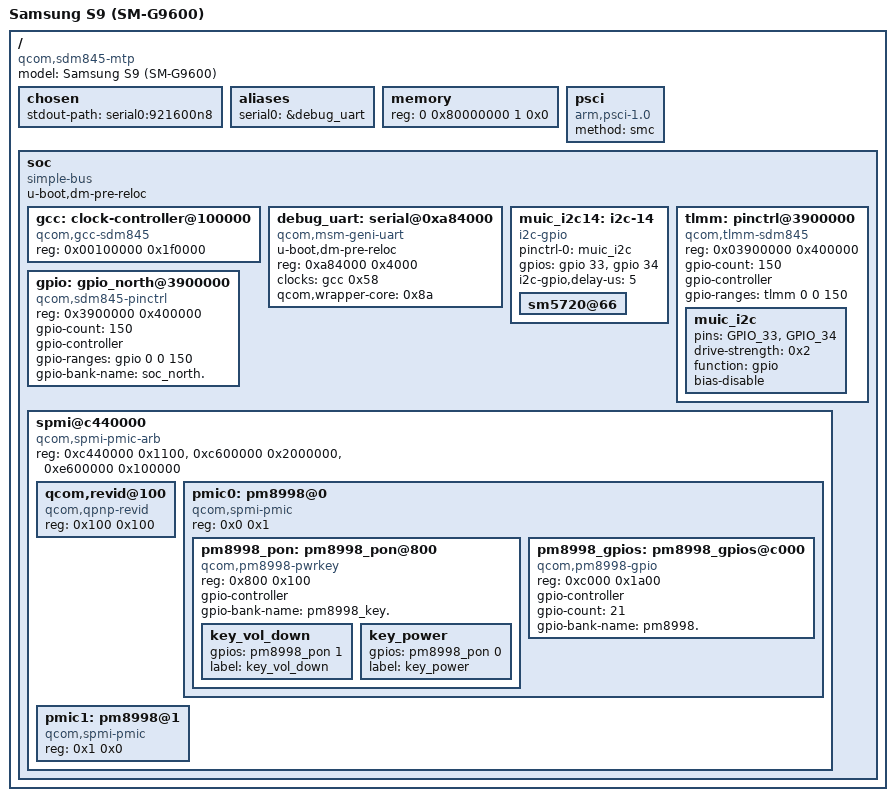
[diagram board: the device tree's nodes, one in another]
/*
 * Qualcomm APQ8096 based Dragonboard 820C board device tree source
 *
 * (C) Copyright 2017 Jorge Ramirez-Ortiz <jorge.ramirez-ortiz@linaro.org>
 *
 * SPDX-License-Identifier:	GPL-2.0+
 */

/dts-v1/;

#include "skeleton64.dtsi"

/ {
	model = "Samsung S9 (SM-G9600)";
	compatible = "qcom,sdm845-mtp", "qcom,sdm845", "qcom,mtp";
	#address-cells = <2>;
	#size-cells = <2>;

	chosen {
		stdout-path = "serial0:921600n8";
	};

	aliases {
		serial0 = &debug_uart;
	};

	memory {
		device_type = "memory";
		reg = <0 0x80000000 1 0x0>;
	};

	psci {
		compatible = "arm,psci-1.0";
		method = "smc";
	};

	soc: soc {
	    u-boot,dm-pre-reloc;
		#address-cells = <1>;
		#size-cells = <1>;
		ranges = <0 0 0 0xffffffff>;
		compatible = "simple-bus";

        gcc: clock-controller@100000 {
			compatible = "qcom,gcc-sdm845";
			reg = <0x00100000 0x1f0000>;
			#clock-cells = <1>;
			#reset-cells = <1>;
			#power-domain-cells = <1>;
		};

        debug_uart: serial@0xa84000 {
            u-boot,dm-pre-reloc;
		    compatible = "qcom,msm-geni-uart";
    		reg = <0xa84000 0x4000>;
    		reg-names = "se_phys";
    		clock-names = "se-clk";
    		clocks = <&gcc 0x58>;
    		//pinctrl-names = "default", "sleep";
    		//pinctrl-0 = <0x88>;
    		//pinctrl-1 = <0x89>;
    		qcom,wrapper-core = <0x8a>;
    		status = "ok";
    	};

        muic_i2c14: i2c-14 {
        	#address-cells = <1>;
        	#size-cells = <0>;
        	compatible = "i2c-gpio";
        	pinctrl-names = "muic";
        	pinctrl-0 = <&muic_i2c>;
        	gpios = <
               	&gpio 33 0 /* sda */
        	    &gpio 34 0 /* scl */
            >;
        	i2c-gpio,delay-us = <5>;

        	sm5720@66 {
        	};
        };

        gpio: gpio_north@3900000 {
			#gpio-cells = <2>;
			compatible = "qcom,sdm845-pinctrl";
			reg = <0x3900000 0x400000>;
			gpio-count = <150>;
			gpio-controller;
			gpio-ranges = <&gpio 0 0 150>;
			gpio-bank-name = "soc_north.";

			/*
			power button:
			volup 0x32
			voldown
			bixby


			.dir_conn_reg = (base == NORTH) ? base + 0xa4000 : \
            			((base == SOUTH) ? base + 0xa8000 : base + 0x9e000), \
			*/
		};

        tlmm: pinctrl@3900000 {
			compatible = "qcom,tlmm-sdm845";
			reg = <0x03900000 0x400000>;
			gpio-count = <150>;
			gpio-controller;
			#gpio-cells = <2>;
			gpio-ranges = <&tlmm 0 0 150>;

            muic_i2c: muic_i2c {
                        pins = "GPIO_33", "GPIO_34";
						drive-strength = <0x2>;
						function = "gpio";
						bias-disable;
			};

			/* DEBUG UART */
            /*
            qup_uart9_default: qup-uart9-default {
				pinmux {
					pins = "gpio4", "gpio5";
					function = "qup9";
				};
			};
			*/
		};

        spmi@c440000 {
			compatible = "qcom,spmi-pmic-arb";
			reg = <0xc440000 0x1100>,
			      <0xc600000 0x2000000>,
			      <0xe600000 0x100000>;
			//reg-names = "core", "chnls", "obsrvr", "intr", "cnfg";
			#address-cells = <0x1>;
			#size-cells = <0x1>;

            qcom,revid@100 {
					compatible = "qcom,qpnp-revid";
					reg = <0x100 0x100>;
					linux,phandle = <0x3ac>;
					phandle = <0x3ac>;
				};

			pmic0: pm8998@0 {
				compatible = "qcom,spmi-pmic";
                reg = <0x0 0x1>;
                #address-cells = <0x1>;
				#size-cells = <0x1>;

				pm8998_pon: pm8998_pon@800 {
					compatible = "qcom,pm8998-pwrkey";
					reg = <0x800 0x100>;
					#gpio-cells = <2>;
					gpio-controller;
					gpio-bank-name="pm8998_key.";

		        key_vol_down {
                		gpios = <&pm8998_pon 1 0>;
                		label = "key_vol_down";
                	};

                	key_power {
                		gpios = <&pm8998_pon 0 0>;
                		label = "key_power";
                	};
				};

				pm8998_gpios: pm8998_gpios@c000 {
					compatible = "qcom,pm8998-gpio";
					reg = <0xc000 0x1a00>;
					gpio-controller;
					gpio-count = <21>;
					#gpio-cells = <2>;
					gpio-bank-name="pm8998.";
				};
			};

            pmic1: pm8998@1 {
				compatible = "qcom,spmi-pmic";
				reg = <0x1 0x0>;
				#address-cells = <0x2>;
				#size-cells = <0x0>;
			};
		};

	};
};
